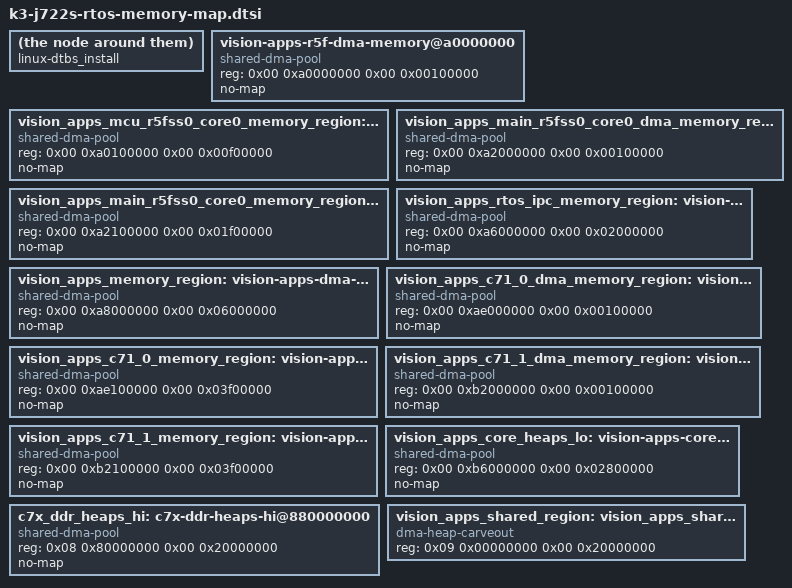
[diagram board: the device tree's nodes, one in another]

 
 /* 
  * IMPORTANT NOTE: Follow the below instructions to apply the updated memory map to the linux dtsi file,
  * 
  * 1. Copy the contents of the generated k3-{SOC}-rtos-memory-map.dtsi file and replace the
  *      reserved_memory section of the k3-{SOC}-rtos-memory-map.dtsi file that is located here:
  *      PSDK_LINUX_PATH/board-support/linux*/arch/arm64/boot/dts/ti
  * 
  * 2. Rebuild the dtb and dtbo from the PSDK_LINUX_PATH directory with the following:
  *      make linux-dtbs
  * 
  * 3. Install the dtb and dtbo to the rootfs/boot folder on the SD card from the same directory with the following:
  *      sudo make linux-dtbs_install; sync
  * 
   */


	vision_apps_mcu_r5fss0_core0_dma_memory_region: vision-apps-r5f-dma-memory@a0000000 {
		compatible = "shared-dma-pool";
		reg = <0x00 0xa0000000 0x00 0x00100000>;
		no-map;
	};
	vision_apps_mcu_r5fss0_core0_memory_region: vision-apps-r5f-memory@a0100000 {
		compatible = "shared-dma-pool";
		reg = <0x00 0xa0100000 0x00 0x00f00000>;
		no-map;
	};
	vision_apps_main_r5fss0_core0_dma_memory_region: vision-apps-r5f-dma-memory@a2000000 {
		compatible = "shared-dma-pool";
		reg = <0x00 0xa2000000 0x00 0x00100000>;
		no-map;
	};
	vision_apps_main_r5fss0_core0_memory_region: vision-apps-r5f-memory@a2100000 {
		compatible = "shared-dma-pool";
		reg = <0x00 0xa2100000 0x00 0x01f00000>;
		no-map;
	};
	vision_apps_rtos_ipc_memory_region: vision-apps-rtos-ipc-memory-region@a6000000 {
		compatible = "shared-dma-pool";
		reg = <0x00 0xa6000000 0x00 0x02000000>;
		no-map;
	};
	vision_apps_memory_region: vision-apps-dma-memory@a8000000 {
		compatible = "shared-dma-pool";
		reg = <0x00 0xa8000000 0x00 0x06000000>;
		no-map;
	};
	vision_apps_c71_0_dma_memory_region: vision-apps-c71-dma-memory@ae000000 {
		compatible = "shared-dma-pool";
		reg = <0x00 0xae000000 0x00 0x00100000>;
		no-map;
	};
	vision_apps_c71_0_memory_region: vision-apps-c71_0-memory@ae100000 {
		compatible = "shared-dma-pool";
		reg = <0x00 0xae100000 0x00 0x03f00000>;
		no-map;
	};
	vision_apps_c71_1_dma_memory_region: vision-apps-c71_1-dma-memory@b2000000 {
		compatible = "shared-dma-pool";
		reg = <0x00 0xb2000000 0x00 0x00100000>;
		no-map;
	};
	vision_apps_c71_1_memory_region: vision-apps-c71_1-memory@b2100000 {
		compatible = "shared-dma-pool";
		reg = <0x00 0xb2100000 0x00 0x03f00000>;
		no-map;
	};
	vision_apps_core_heaps_lo: vision-apps-core-heap-memory-lo@b6000000 {
		compatible = "shared-dma-pool";
		reg = <0x00 0xb6000000 0x00 0x02800000>;
		no-map;
	};
	c7x_ddr_heaps_hi: c7x-ddr-heaps-hi@880000000 {
		compatible = "shared-dma-pool";
		reg = <0x08 0x80000000 0x00 0x20000000>;
		no-map;
	};
	vision_apps_shared_region: vision_apps_shared-memories {
		compatible = "dma-heap-carveout";
		reg = <0x09 0x00000000 0x00 0x20000000>;
	};

